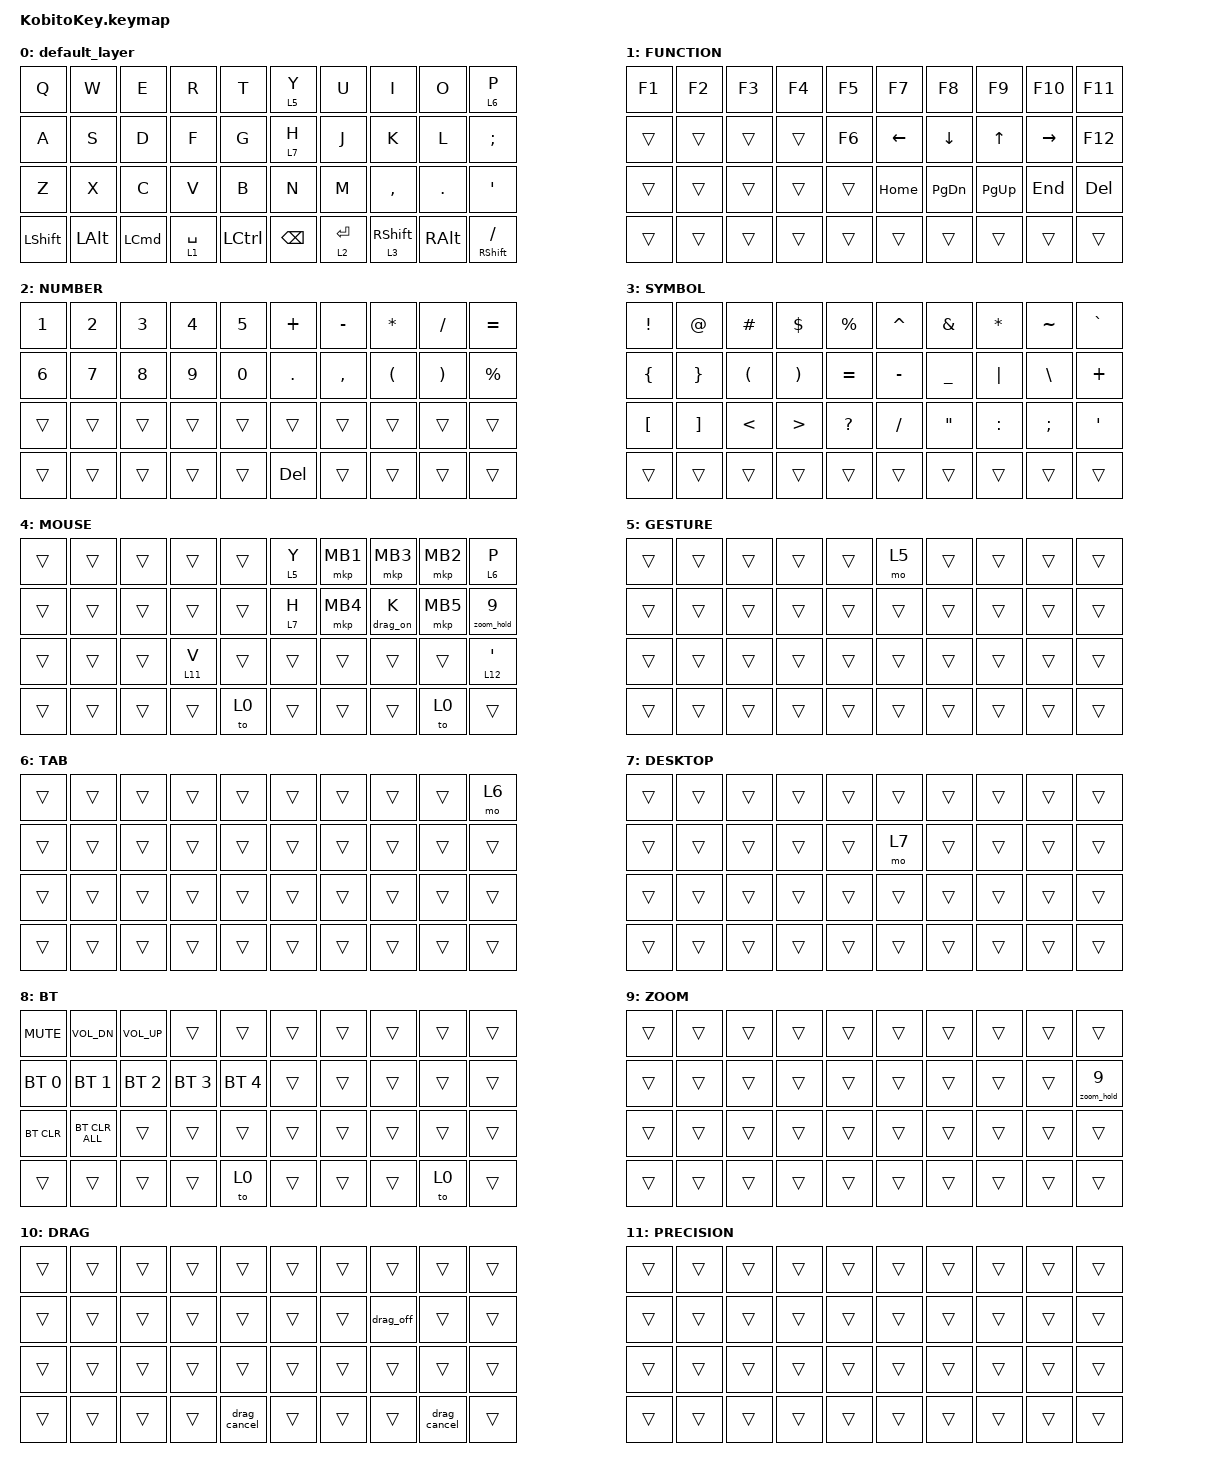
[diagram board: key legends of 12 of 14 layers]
#include <input/processors.dtsi>
#include <behaviors.dtsi>
#include <dt-bindings/zmk/bt.h>
#include <dt-bindings/zmk/keys.h>
#include <dt-bindings/zmk/pointing.h>

/ {
    behaviors {
        /* 押している間: Layer N をアクティブ + LCMD を保持
         * 離した時: Layer N を解除 + LCMD を解除
         * 用途: Layer 9 で左トラックボール=スクロールを Cmd+スクロールに変換し、
         *       macOS / Figma / ブラウザでピンチ風の連続ズームを実現 */
        zoom_hold: zoom_hold {
            compatible = "zmk,behavior-macro-one-param";
            #binding-cells = <1>;
            bindings
                = <&macro_press &kp LCMD>
                , <&macro_press &mo MACRO_PLACEHOLDER>
                , <&macro_pause_for_release>
                , <&macro_release &mo MACRO_PLACEHOLDER>
                , <&macro_release &kp LCMD>
                ;
        };

        /* ドラッグロック: 1押し目で MB1 を押しっぱなしにして Layer 10 へ、
         * Layer 10 の同じキー (drag_off) か左右の安全終了キー
         * (drag_cancel) で解除。長距離ドラッグ中にボタンを押さえ続ける
         * 必要をなくす。 */
        drag_on: drag_on {
            compatible = "zmk,behavior-macro";
            #binding-cells = <0>;
            bindings = <&macro_press &mkp MB1>, <&macro_tap &tog 10>;
        };

        drag_off: drag_off {
            compatible = "zmk,behavior-macro";
            #binding-cells = <0>;
            bindings = <&macro_release &mkp MB1>, <&macro_tap &tog 10>;
        };

        /* ドラッグロックを安全に解除して Layer 0 へ戻る。
         * Layer 10 から &to 0 だけを実行すると MB1 が押下状態のまま残るため、
         * 先に MB1 を明示的に解放する。 */
        drag_cancel: drag_cancel {
            compatible = "zmk,behavior-macro";
            #binding-cells = <0>;
            bindings = <&macro_release &mkp MB1>, <&macro_tap &to 0>;
        };

        /* ドラッグロック用ホールドタップ: タップ = 通常の文字 (Layer 4 誤発動時に
         * k が drag_on に化けるのを防ぐ)、200ms 長押しでドラッグロック開始。
         * 使い方: &dl 0 K (hold 側の drag_on はパラメータ無しなのでダミーの 0) */
        dl: drag_lock_ht {
            compatible = "zmk,behavior-hold-tap";
            #binding-cells = <2>;
            flavor = "tap-preferred";
            tapping-term-ms = <200>;
            bindings = <&drag_on>, <&kp>;
        };

        /* 左トラボで一時発動する SCROLL MENU 専用ホールドタップ。
         * タップは通常文字のまま、180ms 長押しで各トラボ機能レイヤーへ入る。
         * 高番レイヤーの一時発動中でも文字入力を壊さないよう tap-preferred。 */
        menu_lt: scroll_menu_layer_tap {
            compatible = "zmk,behavior-hold-tap";
            #binding-cells = <2>;
            flavor = "tap-preferred";
            tapping-term-ms = <180>;
            bindings = <&mo>, <&kp>;
        };

        /* ZOOM は通常の &mo ではなく、LCMD も同時に保持する zoom_hold を使う。 */
        menu_zoom: scroll_menu_zoom_tap {
            compatible = "zmk,behavior-hold-tap";
            #binding-cells = <2>;
            flavor = "tap-preferred";
            tapping-term-ms = <180>;
            bindings = <&zoom_hold>, <&kp>;
        };
    };

    combos {
        compatible = "zmk,combos";

        /* 英数/かなは全レイヤーで有効。オート発動レイヤー滞在中でも
         * IME 切替を優先し、マウスボタン等への誤爆を防ぐ。
         * 2 本指の押下が 50ms を超えてズレると発動せず df/jk が
         * 出るため 80ms に延長。D+F / J+K のロールはローマ字にも英語にも
         * ほぼ出ないので誤発動リスクは低い。まだ取りこぼすなら 100 へ */
        combo_eisu {
            timeout-ms = <80>;
            key-positions = <12 13>;
            bindings = <&kp LANG2>;
        };

        combo_kana {
            timeout-ms = <80>;
            key-positions = <16 17>;
            bindings = <&kp LANG1>;
        };

        combo_esc {
            timeout-ms = <50>;
            layers = <0>;
            key-positions = <0 1>;
            bindings = <&kp ESC>;
        };

        combo_tab {
            timeout-ms = <50>;
            layers = <0>;
            key-positions = <10 11>;
            bindings = <&kp TAB>;
        };

        combo_bt {
            timeout-ms = <50>;
            layers = <0>;
            key-positions = <35 37>;
            bindings = <&to 8>;
        };
    };

    keymap {
        compatible = "zmk,keymap";

        /* Y/H/P は tap-preferred の hold-tap。通常タップは文字のまま。
         * Layer 4 が切れた後に GESTURE/DESKTOP/TAB 位置を押し続けると、
         * &kp のキーリピートが日本語ローマ字で子音連打 → っっっっっ になる。
         * 実機では H (DESKTOP 位置) の漏れが確認されている。
         * 長押し中だけ &mo で各レイヤーへ入り、離したら戻る。 */
        default_layer {
            bindings = <
&kp Q      &kp W     &kp E     &kp R        &kp T      &menu_lt 5 Y  &kp U        &kp I      &kp O      &menu_lt 6 P
&kp A      &kp S     &kp D     &kp F        &kp G      &menu_lt 7 H  &kp J        &kp K      &kp L      &kp SEMI
&kp Z      &kp X     &kp C     &kp V        &kp B      &kp N       &kp M        &kp COMMA  &kp DOT    &kp APOS
&kp LSHFT  &kp LALT  &kp LCMD  &lt_l 1 SPACE  &kp LCTRL  &kp BSPC  &lt_r 2 ENTER  &lt_r 3 RSHFT  &kp RALT  &mt RSHFT SLASH
            >;
        };

        layer1 {
            label = "FUNCTION";
            bindings = <
&kp F1  &kp F2  &kp F3  &kp F4  &kp F5   &kp F7   &kp F8    &kp F9    &kp F10   &kp F11
&trans  &trans  &trans  &trans  &kp F6   &kp LEFT &kp DOWN  &kp UP    &kp RIGHT &kp F12
&trans  &trans  &trans  &trans  &trans   &kp HOME &kp PG_DN &kp PG_UP &kp END   &kp DEL
&trans  &trans  &trans  &trans  &trans   &trans   &trans    &trans    &trans    &trans
            >;
        };

        layer2 {
            label = "NUMBER";
            bindings = <
&kp N1  &kp N2  &kp N3  &kp N4  &kp N5  &kp PLUS   &kp MINUS  &kp ASTRK  &kp SLASH  &kp EQUAL
&kp N6  &kp N7  &kp N8  &kp N9  &kp N0  &kp DOT    &kp COMMA  &kp LPAR   &kp RPAR   &kp PRCNT
&trans  &trans  &trans  &trans  &trans  &trans     &trans     &trans     &trans     &trans
&trans  &trans  &trans  &trans  &trans  &kp DEL    &trans     &trans     &trans     &trans
            >;
        };

        layer3 {
            label = "SYMBOL";
            bindings = <
&kp EXCL  &kp AT    &kp HASH  &kp DLLR  &kp PRCNT  &kp CARET  &kp AMPS   &kp ASTRK  &kp TILDE  &kp GRAVE
&kp LBRC  &kp RBRC  &kp LPAR  &kp RPAR  &kp EQUAL  &kp MINUS  &kp UNDER  &kp PIPE   &kp BSLH   &kp PLUS
&kp LBKT  &kp RBKT  &kp LT    &kp GT    &kp QMARK  &kp SLASH  &kp DQT    &kp COLON  &kp SEMI   &kp APOS
&trans    &trans    &trans    &trans    &trans     &trans     &trans     &trans     &trans     &trans
            >;
        };

        /* pos 17 (K) 長押し: ドラッグロック開始 (タップは k のまま)
         * pos 23 (V) 長押し: 押している間 右トラボ精密モード (タップは v)
         * pos 29 (') 長押し: 押している間 左トラボ横スクロール (タップは ')
         * Y/H/P は素の &mo だとオートマウスレイヤー滞在中のタップが無反応に
         * なる (excluded-positions でレイヤーも解除されない) ため、
         * Layer 13 と同じ menu_lt でタップ=文字 / 長押し=各レイヤーにする */
        layer4 {
            label = "MOUSE";
            bindings = <
&trans        &trans        &trans        &trans      &trans  &menu_lt 5 Y  &mkp MB1  &mkp MB3  &mkp MB2  &menu_lt 6 P
&trans        &trans        &trans        &trans      &trans  &menu_lt 7 H  &mkp MB4  &dl 0 K   &mkp MB5  &zoom_hold 9
&trans        &trans        &trans        &lt 11 V    &trans  &trans  &trans    &trans    &trans    &lt 12 APOS
&trans        &trans        &trans        &trans      &to 0   &trans  &trans    &trans    &to 0     &trans
            >;
        };

        layer5 {
            label = "GESTURE";
            bindings = <
&trans  &trans  &trans  &trans  &trans  &mo 5   &trans  &trans  &trans  &trans
&trans  &trans  &trans  &trans  &trans  &trans  &trans  &trans  &trans  &trans
&trans  &trans  &trans  &trans  &trans  &trans  &trans  &trans  &trans  &trans
&trans  &trans  &trans  &trans  &trans  &trans  &trans  &trans  &trans  &trans
            >;
        };

        layer6 {
            label = "TAB";
            bindings = <
&trans  &trans  &trans  &trans  &trans  &trans  &trans  &trans  &trans  &mo 6
&trans  &trans  &trans  &trans  &trans  &trans  &trans  &trans  &trans  &trans
&trans  &trans  &trans  &trans  &trans  &trans  &trans  &trans  &trans  &trans
&trans  &trans  &trans  &trans  &trans  &trans  &trans  &trans  &trans  &trans
            >;
        };

        layer7 {
            label = "DESKTOP";
            bindings = <
&trans  &trans  &trans  &trans  &trans  &trans  &trans  &trans  &trans  &trans
&trans  &trans  &trans  &trans  &trans  &mo 7   &trans  &trans  &trans  &trans
&trans  &trans  &trans  &trans  &trans  &trans  &trans  &trans  &trans  &trans
&trans  &trans  &trans  &trans  &trans  &trans  &trans  &trans  &trans  &trans
            >;
        };

        layer8 {
            label = "BT";
            bindings = <
&kp C_MUTE    &kp C_VOL_DN  &kp C_VOL_UP  &trans  &trans          &trans  &trans  &trans  &trans  &trans
&bt BT_SEL 0  &bt BT_SEL 1  &bt BT_SEL 2  &bt BT_SEL 3  &bt BT_SEL 4  &trans  &trans  &trans  &trans  &trans
&bt BT_CLR    &bt BT_CLR_ALL &trans        &trans        &trans        &trans  &trans  &trans  &trans  &trans
&trans        &trans         &trans        &trans        &to 0         &trans  &trans  &trans  &to 0   &trans
            >;
        };

        layer9 {
            label = "ZOOM";
            bindings = <
&trans  &trans  &trans  &trans  &trans  &trans  &trans  &trans  &trans  &trans
&trans  &trans  &trans  &trans  &trans  &trans  &trans  &trans  &trans  &zoom_hold 9
&trans  &trans  &trans  &trans  &trans  &trans  &trans  &trans  &trans  &trans
&trans  &trans  &trans  &trans  &trans  &trans  &trans  &trans  &trans  &trans
            >;
        };

        /* MB1 押しっぱなし中。pos 17 の drag_off で解除。
         * Layer 4 の &to 0 が透過してくる pos 34/38 は drag_cancel で
         * MB1 を解放してから Layer 0 へ戻す。 */
        layer10 {
            label = "DRAG";
            bindings = <
&trans  &trans  &trans  &trans  &trans  &trans  &trans  &trans     &trans  &trans
&trans  &trans  &trans  &trans  &trans  &trans  &trans  &drag_off  &trans  &trans
&trans  &trans  &trans  &trans  &trans  &trans  &trans  &trans     &trans  &trans
&trans  &trans  &trans  &trans  &drag_cancel  &trans  &trans  &trans  &drag_cancel  &trans
            >;
        };

        /* 右トラボ精密モード。実体は overlay の input-processor 分岐 */
        layer11 {
            label = "PRECISION";
            bindings = <
&trans  &trans  &trans  &trans  &trans  &trans  &trans  &trans  &trans  &trans
&trans  &trans  &trans  &trans  &trans  &trans  &trans  &trans  &trans  &trans
&trans  &trans  &trans  &trans  &trans  &trans  &trans  &trans  &trans  &trans
&trans  &trans  &trans  &trans  &trans  &trans  &trans  &trans  &trans  &trans
            >;
        };

        /* 左トラボ横スクロールモード。実体は overlay の input-processor 分岐 */
        layer12 {
            label = "HSCROLL";
            bindings = <
&trans  &trans  &trans  &trans  &trans  &trans  &trans  &trans  &trans  &trans
&trans  &trans  &trans  &trans  &trans  &trans  &trans  &trans  &trans  &trans
&trans  &trans  &trans  &trans  &trans  &trans  &trans  &trans  &trans  &trans
&trans  &trans  &trans  &trans  &trans  &trans  &trans  &trans  &trans  &trans
            >;
        };

        /* 左トラボ操作後 2.5 秒だけ発動する安全な機能入口。
         * タップは元の文字、長押し中だけ各トラボ機能へ入る。
         * マウスボタンは置かず、左右親指の &to 0 で即座に終了できる。 */
        layer13 {
            label = "SCROLL MENU";
            bindings = <
&trans  &trans  &trans  &trans  &trans  &menu_lt 5 Y  &trans  &trans  &trans  &menu_lt 6 P
&trans  &trans  &trans  &trans  &trans  &menu_lt 7 H  &trans  &trans  &trans  &menu_zoom 9 SEMI
&trans  &trans  &trans  &trans  &trans  &trans        &trans  &trans  &trans  &menu_lt 12 APOS
&trans  &trans  &trans  &trans  &to 0   &trans        &trans  &trans  &to 0   &trans
            >;
        };
    };
};

/* lt (layer-tap) を hold-preferred + 短めの tapping-term に変更。
 * デフォルト (tap-preferred / 200ms) や balanced では押し方次第で
 * lt 3 RSHFT + `-` が `H` に化ける症状が残った。hold-preferred は
 * 別キーが押された瞬間に hold を確定するので、押し方を問わず Layer 入り
 * が確定する。副作用として lt 単独タップ (Space/Enter/RSHFT) を別キーと
 * 連続入力すると hold 誤判定されやすくなるため、tapping-term を 180ms
 * と短めにし、quick-tap-ms=125 で連続タップ時の取りこぼしを救う。
 *
 * require-prior-idle-ms は当初 150ms だったが、Layer 切替の反応が
 * 鈍く感じたため 90ms に短縮。タイピング後 90ms 経てば hold 判定が
 * 通常通り効くので、文章中の親指 lt も実用域。
 *
 * 注意: require-prior-idle-ms は修飾キーでは効かない (ZMK の
 * keycode_state_changed_listener は !is_mod() のキーでしか last_tapped を
 * 更新しない)。Cmd を押しっぱなしで親指 lt を 180ms 保持すると hold が
 * 確定して文字が消える。左親指の Space だけは lt_l の retro-tap で
 * 救ってある。 */
&lt {
    flavor = "hold-preferred";
    tapping-term-ms = <180>;
    quick-tap-ms = <125>;
    require-prior-idle-ms = <90>;
};

/* mt (mod-tap) も lt と同じ方針。&mt RSHFT SLASH (右親指 /) で
 * タイピング中に親指がかすって Shift+α に化けるのを防ぐため
 * require-prior-idle-ms を効かせる。 */
&mt {
    flavor = "hold-preferred";
    tapping-term-ms = <180>;
    quick-tap-ms = <125>;
    require-prior-idle-ms = <90>;
};

/ {
    behaviors {
        /* 左親指 lt。retro-tap は他のキーを押さずに離した時だけ tap へ
         * ロールバックするので、Cmd+Ctrl+Space / Cmd+Space の Space が
         * 消えなくなる (修飾キーは Space より先に押されるため hold-tap の
         * 言う『他のキーの押下』に数えられない)。Layer 1 の発動は次のキーを
         * 押す瞬間まで保留されるだけなので使い勝手は変わらない。
         * 副作用: 長押し中は Layer 1 未発動なので LED が光らない。
         * 離す時は Space を先に。修飾キーを先に離すと hold へ昇格する。
         *
         * positional hold-tap (hold-trigger-key-positions +
         * hold-trigger-on-release) は復活させないこと。hold-preferred が
         * 他キーの『押下』で hold を確定するのに対し、位置が記録されるのは
         * 『離した』時なので decide_positional_hold が常に空振りする。
         * そもそも positional は lt より後に押されたキーしか見ないため、
         * 修飾キーを先に押す並びは原理的に対象外。 */
        lt_l: lt_left_thumb {
            compatible = "zmk,behavior-hold-tap";
            #binding-cells = <2>;
            flavor = "hold-preferred";
            tapping-term-ms = <180>;
            quick-tap-ms = <125>;
            require-prior-idle-ms = <90>;
            bindings = <&mo>, <&kp>;
            retro-tap;
        };

        /* 右親指 lt。retro-tap は付けない。Layer 2/3 に入ろうとして
         * 思い直しただけで Enter が飛ぶ実害の方が大きいため。 */
        lt_r: lt_right_thumb {
            compatible = "zmk,behavior-hold-tap";
            #binding-cells = <2>;
            flavor = "hold-preferred";
            tapping-term-ms = <180>;
            quick-tap-ms = <125>;
            require-prior-idle-ms = <90>;
            bindings = <&mo>, <&kp>;
        };
    };
};
